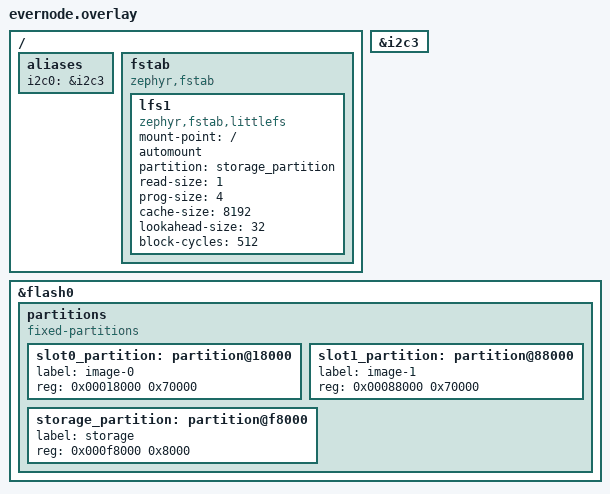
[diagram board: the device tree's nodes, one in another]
/ {
    aliases {
        i2c0 = &i2c3;
    };

    fstab {
        compatible = "zephyr,fstab";
        lfs1: lfs1 {
            compatible = "zephyr,fstab,littlefs";
            mount-point = "/";
            automount;
            partition = <&storage_partition>;
            read-size = <1>;
            prog-size = <4>;
            cache-size = <8192>;
            lookahead-size = <32>;
            block-cycles = <512>;
        };
    };
};

&i2c3 {
    status = "okay";
};

/delete-node/ &slot0_partition;
/delete-node/ &slot1_partition;
/delete-node/ &storage_partition;

&flash0 {
    partitions {
        compatible = "fixed-partitions";
        #address-cells = <1>;
        #size-cells = <1>;

        slot0_partition: partition@18000 {
            label = "image-0";
            reg = <0x00018000 0x70000>;
        };
        slot1_partition: partition@88000 {
            label = "image-1";
            reg = <0x00088000 0x70000>;
        };
        /* Set 32KB of storage at the end of the 1024KB of flash */
        storage_partition: partition@f8000 {
            label = "storage";
            reg = <0x000f8000 0x8000>;
        };
    };
};
